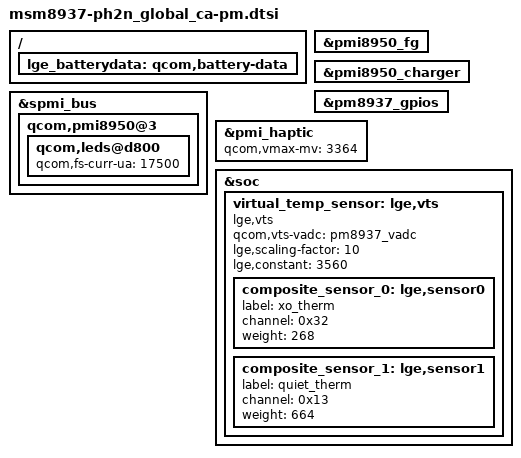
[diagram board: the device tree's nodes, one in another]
/*
 * Copyright (c) 2015, The Linux Foundation. All rights reserved.
 *
 * This program is free software; you can redistribute it and/or modify
 * it under the terms of the GNU General Public License version 2 and
 * only version 2 as published by the Free Software Foundation.
 *
 * This program is distributed in the hope that it will be useful,
 * but WITHOUT ANY WARRANTY; without even the implied warranty of
 * MERCHANTABILITY or FITNESS FOR A PARTICULAR PURPOSE.  See the
 * GNU General Public License for more details.
 */

/{
	lge_batterydata: qcom,battery-data {
		#include "../battery_profile/LGE_BL45B1F_LGC_3000mAh.dtsi"
		#include "../battery_profile/LGE_BL45B1F_Tocad_3000mAh.dtsi"
	};
};

&pmi8950_fg {
};

&pmi8950_charger {
};

/* PM8937 GPIO configuration */
&pm8937_gpios {
 };

&spmi_bus {
	qcom,pmi8950@3 {
		qcom,leds@d800 {
			qcom,fs-curr-ua = <17500>;
			/delete-property/ qcom,en-ext-pfet-sc-pro;
		};
	};
};

&pmi_haptic{
	status = "ok";
	qcom,vmax-mv = <3364>;
};

&soc {
	/* vst = (0.268*xo_therm) + (0.664*quiet_therm) + 3.56 */
	virtual_temp_sensor: lge,vts {
		compatible = "lge,vts";
		qcom,vts-vadc = <&pm8937_vadc>;
		lge,scaling-factor= <10>;
		lge,constant = <3560>;
		composite_sensor_0: lge,sensor0 {
			label = "xo_therm";
			channel = <0x32>;
			weight = <268>;
		};
		composite_sensor_1: lge,sensor1 {
			label = "quiet_therm";
			channel = <0x13>;
			weight = <664>;
		};
	};
};
